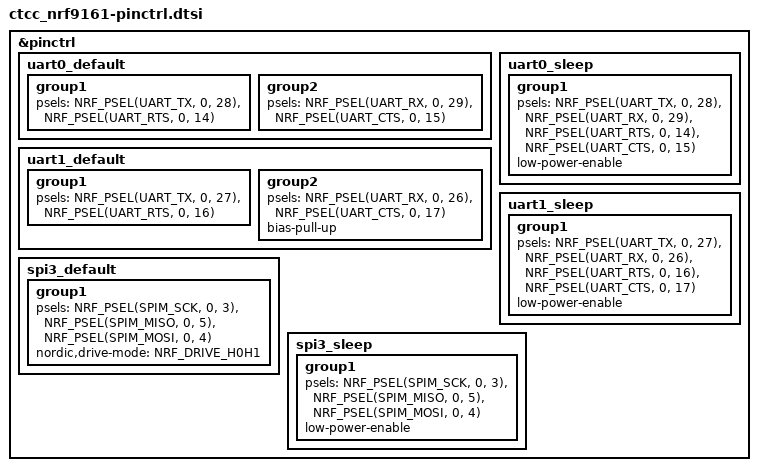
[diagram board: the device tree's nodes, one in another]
/*
 * Copyright (c) 2024 CTHINGS.CO
 * SPDX-License-Identifier: Apache-2.0
 */

&pinctrl {
	uart0_default: uart0_default {
		group1 {
			psels = <NRF_PSEL(UART_TX, 0, 28)>,
				<NRF_PSEL(UART_RTS, 0, 14)>;
		};
		group2 {
			psels = <NRF_PSEL(UART_RX, 0, 29)>,
				<NRF_PSEL(UART_CTS, 0, 15)>;
		};
	};

	uart0_sleep: uart0_sleep {
		group1 {
			psels = <NRF_PSEL(UART_TX, 0, 28)>,
				<NRF_PSEL(UART_RX, 0, 29)>,
				<NRF_PSEL(UART_RTS, 0, 14)>,
				<NRF_PSEL(UART_CTS, 0, 15)>;
			low-power-enable;
		};
	};

	uart1_default: uart1_default {
		group1 {
			psels = <NRF_PSEL(UART_TX, 0, 27)>,
				<NRF_PSEL(UART_RTS, 0, 16)>;
		};
		group2 {
			psels = <NRF_PSEL(UART_RX, 0, 26)>,
				<NRF_PSEL(UART_CTS, 0, 17)>;
			bias-pull-up;
		};
	};

	uart1_sleep: uart1_sleep {
		group1 {
			psels = <NRF_PSEL(UART_TX, 0, 27)>,
				<NRF_PSEL(UART_RX, 0, 26)>,
				<NRF_PSEL(UART_RTS, 0, 16)>,
				<NRF_PSEL(UART_CTS, 0, 17)>;
			low-power-enable;
		};
	};

	spi3_default: spi3_default {
		group1 {
			psels = <NRF_PSEL(SPIM_SCK, 0, 3)>,
				<NRF_PSEL(SPIM_MISO, 0, 5)>,
				<NRF_PSEL(SPIM_MOSI, 0, 4)>;
			nordic,drive-mode = <NRF_DRIVE_H0H1>;
		};
	};

	spi3_sleep: spi3_sleep {
		group1 {
			psels = <NRF_PSEL(SPIM_SCK, 0, 3)>,
				<NRF_PSEL(SPIM_MISO, 0, 5)>,
				<NRF_PSEL(SPIM_MOSI, 0, 4)>;
			low-power-enable;
		};
	};
};
